VERSION "All_Common"

NS_ :

BS_:

BU_: PCM UNKNOWN

BO_ 983 PCM_0x3D7: 8 PCM
 SG_ MULTIPLEX_HEADER : 0|8@1+ (1,0) [0|255] ""  UNKNOWN
 SG_ RETAINED_BANK_A_WORD_0_PAGE_0 m0 : 15|16@0+ (1,0) [0|65535] ""  UNKNOWN
 SG_ RETAINED_BANK_A_WORD_0_PAGE_1 m1 : 15|16@0+ (1,0) [0|65535] ""  UNKNOWN
 SG_ RETAINED_BANK_A_WORD_1_PAGE_0 m0 : 31|16@0+ (1,0) [0|65535] ""  UNKNOWN
 SG_ RETAINED_BANK_A_WORD_1_PAGE_1 m1 : 31|16@0+ (1,0) [0|65535] ""  UNKNOWN
 SG_ RETAINED_BANK_A_WORD_2_PAGE_0 m0 : 47|16@0+ (1,0) [0|65535] ""  UNKNOWN
 SG_ RETAINED_BANK_A_WORD_2_PAGE_1 m1 : 47|16@0+ (1,0) [0|65535] ""  UNKNOWN
 SG_ CHECKSUM : 56|4@1+ (1,0) [0|15] ""  UNKNOWN
 SG_ COUNTER : 60|2@1+ (1,0) [0|3] ""  UNKNOWN
 SG_ PAGE_INDEX M : 62|1@1+ (1,0) [0|1] ""  UNKNOWN
 SG_ PAGE_INDEX_HIGH_BIT : 63|1@1+ (1,0) [0|1] ""  UNKNOWN
VAL_ 983 PAGE_INDEX 0 "SLOTS0_TO2" 1 "SLOTS3_TO5" ;
SG_MUL_VAL_ 983 RETAINED_BANK_A_WORD_0_PAGE_0 PAGE_INDEX 0-0;
SG_MUL_VAL_ 983 RETAINED_BANK_A_WORD_0_PAGE_1 PAGE_INDEX 1-1;
SG_MUL_VAL_ 983 RETAINED_BANK_A_WORD_1_PAGE_0 PAGE_INDEX 0-0;
SG_MUL_VAL_ 983 RETAINED_BANK_A_WORD_1_PAGE_1 PAGE_INDEX 1-1;
SG_MUL_VAL_ 983 RETAINED_BANK_A_WORD_2_PAGE_0 PAGE_INDEX 0-0;
SG_MUL_VAL_ 983 RETAINED_BANK_A_WORD_2_PAGE_1 PAGE_INDEX 1-1;

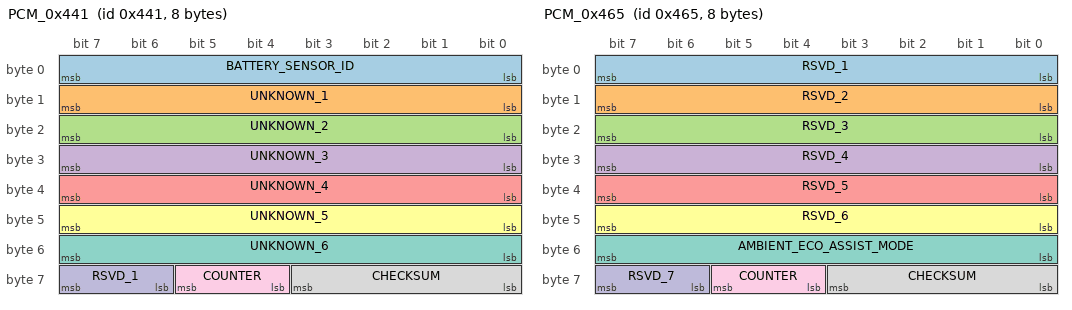
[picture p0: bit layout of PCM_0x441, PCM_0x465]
BO_ 1089 PCM_0x441: 8 PCM
 SG_ BATTERY_SENSOR_ID : 0|8@1+ (1,0) [0|255] ""  UNKNOWN
 SG_ UNKNOWN_1 : 8|8@1+ (1,0) [0|255] ""  UNKNOWN
 SG_ UNKNOWN_2 : 16|8@1+ (1,0) [0|255] ""  UNKNOWN
 SG_ UNKNOWN_3 : 24|8@1+ (1,0) [0|255] ""  UNKNOWN
 SG_ UNKNOWN_4 : 32|8@1+ (1,0) [0|255] ""  UNKNOWN
 SG_ UNKNOWN_5 : 40|8@1+ (1,0) [0|255] ""  UNKNOWN
 SG_ UNKNOWN_6 : 48|8@1+ (1,0) [0|255] ""  UNKNOWN
 SG_ CHECKSUM : 56|4@1+ (1,0) [0|15] ""  UNKNOWN
 SG_ COUNTER : 60|2@1+ (1,0) [0|3] ""  UNKNOWN
 SG_ RSVD_1 : 62|2@1+ (1,0) [0|3] ""  UNKNOWN

BO_ 1125 PCM_0x465: 8 PCM
 SG_ RSVD_1 : 0|8@1+ (1,0) [0|255] ""  UNKNOWN
 SG_ RSVD_2 : 8|8@1+ (1,0) [0|255] ""  UNKNOWN
 SG_ RSVD_3 : 16|8@1+ (1,0) [0|255] ""  UNKNOWN
 SG_ RSVD_4 : 24|8@1+ (1,0) [0|255] ""  UNKNOWN
 SG_ RSVD_5 : 32|8@1+ (1,0) [0|255] ""  UNKNOWN
 SG_ RSVD_6 : 40|8@1+ (1,0) [0|255] ""  UNKNOWN
 SG_ AMBIENT_ECO_ASSIST_MODE : 48|8@1+ (1,0) [0|255] ""  UNKNOWN
 SG_ CHECKSUM : 56|4@1+ (1,0) [0|15] ""  UNKNOWN
 SG_ COUNTER : 60|2@1+ (1,0) [0|3] ""  UNKNOWN
 SG_ RSVD_7 : 62|2@1+ (1,0) [0|3] ""  UNKNOWN
VAL_ 1125 AMBIENT_ECO_ASSIST_MODE 1 "WHITE" 2 "LIGHT_GREEN" 3 "GREEN" ;
